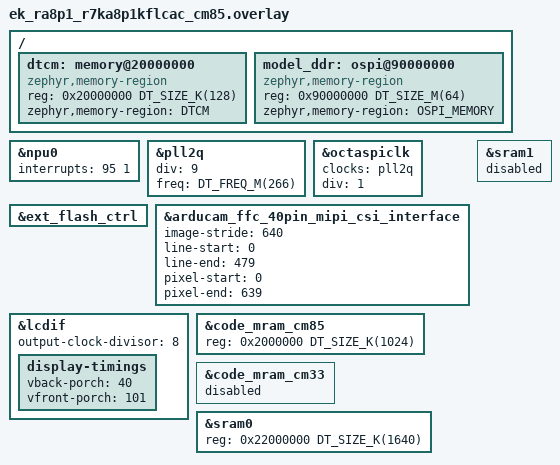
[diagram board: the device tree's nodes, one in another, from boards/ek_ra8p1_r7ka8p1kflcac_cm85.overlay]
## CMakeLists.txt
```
# Copyright 2026 Renesas Electronics Corporation
# SPDX-License-Identifier: Apache-2.0

cmake_minimum_required(VERSION 3.24)

set(CMAKE_SKIP_INSTALL_RULES
    ON
    CACHE BOOL "" FORCE
)

set(ET_PTE_FILE_PATH
    ""
    CACHE FILEPATH "Path to the ExecuTorch .pte (or .bpte) model to embed"
)
set(ET_PTE_SECTION
    "network_model_sec"
    CACHE STRING "Section attribute used for the generated model data"
)

if(NOT ET_PTE_FILE_PATH)
  message(
    FATAL_ERROR
      "ET_PTE_FILE_PATH must point to the ExecuTorch .pte (or .bpte) model to embed."
  )
endif()

if(NOT IS_ABSOLUTE "${ET_PTE_FILE_PATH}")
  get_filename_component(
    ET_PTE_FILE_PATH "${ET_PTE_FILE_PATH}" ABSOLUTE BASE_DIR
    "${CMAKE_CURRENT_SOURCE_DIR}"
  )
endif()

if(NOT EXISTS "${ET_PTE_FILE_PATH}")
  message(
    FATAL_ERROR
      "Could not find ExecuTorch model at ET_PTE_FILE_PATH: ${ET_PTE_FILE_PATH}"
  )
endif()

set(ET_PTE_FILE_PATH
    "${ET_PTE_FILE_PATH}"
    CACHE FILEPATH "Path to the ExecuTorch .pte (or .bpte) model to embed"
          FORCE
)

find_package(
  Python3
  COMPONENTS Interpreter
  REQUIRED
)

# Needed early (before project()) just for ZEPHYR_EXECUTORCH_MODULE_DIR, to
# locate gen_oplist.py without assuming this sample's own path nests inside
# the executorch checkout.
find_package(Zephyr REQUIRED HINTS $ENV{ZEPHYR_BASE})

execute_process(
  COMMAND
    ${Python3_EXECUTABLE}
    "${ZEPHYR_EXECUTORCH_MODULE_DIR}/codegen/tools/gen_oplist.py"
    --model_file_path=${ET_PTE_FILE_PATH}
    --output_path=${CMAKE_CURRENT_BINARY_DIR}/temp.yaml
  RESULT_VARIABLE GEN_OPLIST_RESULT
  OUTPUT_VARIABLE CMD_RESULT
  ERROR_VARIABLE GEN_OPLIST_ERROR
)

if(NOT GEN_OPLIST_RESULT EQUAL 0)
  message(
    FATAL_ERROR
      "gen_oplist.py failed with exit code ${GEN_OPLIST_RESULT}: ${GEN_OPLIST_ERROR}"
  )
endif()

if(CMD_RESULT MATCHES "aten::" OR CMD_RESULT MATCHES "dim_order_ops::")
  set(FOUND_OPS_IN_FILE "true")
else()
  set(FOUND_OPS_IN_FILE "false")
endif()

if(${FOUND_OPS_IN_FILE})
  set(EXECUTORCH_SELECT_OPS_LIST "")
  set(EXECUTORCH_SELECT_OPS_MODEL
      "${ET_PTE_FILE_PATH}"
      CACHE STRING "Select operators from this ExecuTorch model" FORCE
  )
  set(_EXECUTORCH_GEN_ZEPHYR_PORTABLE_OPS ON)
  message(
    "gen_oplist:  EXECUTORCH_SELECT_OPS_MODEL=${ET_PTE_FILE_PATH} is used to auto generate ops from"
  )
else()
  set(EXECUTORCH_SELECT_OPS_LIST "")
  set(EXECUTORCH_SELECT_OPS_MODEL "")
  set(_EXECUTORCH_GEN_ZEPHYR_PORTABLE_OPS OFF)
  message(
    "gen_oplist: No non-delegated ops were found in ${ET_PTE_FILE_PATH}; no ops added to build"
  )
endif()

dt_nodelabel(model_ddr_path NODELABEL "model_ddr")
if(model_ddr_path)
  configure_file(
    model_section.ld.in ${CMAKE_CURRENT_BINARY_DIR}/model_section.ld @ONLY
  )
  zephyr_linker_sources(SECTIONS ${CMAKE_CURRENT_BINARY_DIR}/model_section.ld)

  # EK-RA8P1's OSPI controller reads back bytes as b1-b0-b3-b2 when running
  # in octa mode, so the model PTE blob linked into model_ddr (ET_PTE_SECTION,
  # see model_section.ld.in) must be byte-swapped in the flashed hex image or
  # it reads back scrambled at runtime. Split the final image into an
  # internal-flash part (PTE section removed) and an OSPI-only part (PTE
  # section only), byte-swap the OSPI part, then remerge.
  find_program(SREC_CAT srec_cat REQUIRED)

  set(MERGED_HEX ${PROJECT_BINARY_DIR}/zephyr_merged.hex)

  add_custom_target(
    split_flash ALL
    DEPENDS zephyr_final
    # Main internal flash image, OSPI section removed
    COMMAND
      ${CMAKE_OBJCOPY} -R ${ET_PTE_SECTION} -O ihex
      $<TARGET_FILE:zephyr_final>
      ${PROJECT_BINARY_DIR}/zephyr_internal.hex
    # OSPI data only (intermediate)
    COMMAND
      ${CMAKE_OBJCOPY} -j ${ET_PTE_SECTION} -O ihex
      $<TARGET_FILE:zephyr_final>
      ${PROJECT_BINARY_DIR}/zephyr_ospi_raw.hex
    # Byte-swap the OSPI hex
    COMMAND
      ${SREC_CAT} ${PROJECT_BINARY_DIR}/zephyr_ospi_raw.hex -Intel
      -byte_swap 2 -o ${PROJECT_BINARY_DIR}/zephyr_ospi.hex -Intel
    COMMAND
      ${SREC_CAT} ${PROJECT_BINARY_DIR}/zephyr_internal.hex -Intel
      ${PROJECT_BINARY_DIR}/zephyr_ospi.hex -Intel -o ${MERGED_HEX}
      -Intel
    COMMENT "Splitting and byte-swapping OSPI (${ET_PTE_SECTION}) flash image for octa-mode read order"
  )
endif()

# Route the method/temp allocator pools to external SDRAM when the board
# provides one, since some boards' on-chip SRAM is too small to hold both
# pools for larger models (e.g. MobileNetV2 needs ~3 MiB combined).
dt_nodelabel(pool_sdram_path NODELABEL "sdram1")
if(pool_sdram_path)
  configure_file(
    pool_section.ld.in ${CMAKE_CURRENT_BINARY_DIR}/pool_section.ld @ONLY
  )
  zephyr_linker_sources(SECTIONS ${CMAKE_CURRENT_BINARY_DIR}/pool_section.ld)
endif()

project(executorch_mv2_ethosu_renesas)

set(CMAKE_CXX_FLAGS
    "${CMAKE_CXX_FLAGS} -Wall -Wno-switch -Wno-float-conversion -Wno-double-promotion -Wno-psabi -ffunction-sections -fdata-sections"
)

if(NOT DEFINED EXECUTORCH_DIR)
  message(
    STATUS
      "ZEPHYR_EXECUTORCH_MODULE_DIR set to : ${ZEPHYR_EXECUTORCH_MODULE_DIR}"
  )
  if(DEFINED ZEPHYR_EXECUTORCH_MODULE_DIR)
    set(EXECUTORCH_DIR ${ZEPHYR_EXECUTORCH_MODULE_DIR})
    message(
      STATUS "Using Zephyr module discovery: EXECUTORCH_DIR=${EXECUTORCH_DIR}"
    )
  else()
    message(
      FATAL_ERROR
        "ExecuTorch module not found. Ensure it's properly configured in your Zephyr workspace."
    )
  endif()
else()
  message(STATUS "Using predefined EXECUTORCH_DIR=${EXECUTORCH_DIR}")
endif()

set(EXECUTORCH_ROOT ${EXECUTORCH_DIR})
include(${EXECUTORCH_DIR}/tools/cmake/Utils.cmake)

if(NOT TARGET portable_kernels)
  set(EXECUTORCH_PORTABLE_BUILD_KERNELS_ONLY ON)
  add_subdirectory(
    ${EXECUTORCH_DIR}/kernels/portable
    ${CMAKE_CURRENT_BINARY_DIR}/executorch/kernels/portable
  )
  unset(EXECUTORCH_PORTABLE_BUILD_KERNELS_ONLY)
endif()
set(EXECUTORCH_OPS_LIB "")
if(_EXECUTORCH_GEN_ZEPHYR_PORTABLE_OPS)
  include(${EXECUTORCH_DIR}/tools/cmake/Codegen.cmake)
  if(NOT DEFINED EXECUTORCH_ENABLE_DTYPE_SELECTIVE_BUILD)
    set(EXECUTORCH_ENABLE_DTYPE_SELECTIVE_BUILD "")
  endif()
  gen_selected_ops(
    LIB_NAME
    "cpu_portable_ops_lib"
    OPS_SCHEMA_YAML
    ""
    ROOT_OPS
    "${EXECUTORCH_SELECT_OPS_LIST}"
    INCLUDE_ALL_OPS
    ""
    OPS_FROM_MODEL
    "${EXECUTORCH_SELECT_OPS_MODEL}"
    DTYPE_SELECTIVE_BUILD
    "${EXECUTORCH_ENABLE_DTYPE_SELECTIVE_BUILD}"
  )
  generate_bindings_for_kernels(
    LIB_NAME "cpu_portable_ops_lib" FUNCTIONS_YAML
    ${EXECUTORCH_DIR}/kernels/portable/functions.yaml DTYPE_SELECTIVE_BUILD
    "${EXECUTORCH_ENABLE_DTYPE_SELECTIVE_BUILD}"
  )
  gen_operators_lib(
    LIB_NAME
    "cpu_portable_ops_lib"
    KERNEL_LIBS
    portable_kernels
    DEPS
    executorch
    DTYPE_SELECTIVE_BUILD
    "${EXECUTORCH_ENABLE_DTYPE_SELECTIVE_BUILD}"
  )
  set(EXECUTORCH_OPS_LIB "cpu_portable_ops_lib")
endif()

set(_local_flatcc_root ${CMAKE_BINARY_DIR}/flatcc_src)
if(NOT EXISTS ${_local_flatcc_root}/CMakeLists.txt)
  file(MAKE_DIRECTORY ${_local_flatcc_root})
  execute_process(
    COMMAND ${CMAKE_COMMAND} -E copy_directory
            ${EXECUTORCH_DIR}/third-party/flatcc ${_local_flatcc_root}
  )
endif()
set(EXECUTORCH_FLATCC_SOURCE_ROOT
    ${_local_flatcc_root}
    CACHE PATH "" FORCE
)
set(EXECUTORCH_FLATCC_INSTALL_ROOT
    ${_local_flatcc_root}
    CACHE PATH "" FORCE
)

set(app_sources
    src/main.c
    src/camera.c
    src/display.c
    src/ai_processing.cpp
    ${EXECUTORCH_DIR}/examples/arm/executor_runner/arm_memory_allocator.cpp
)
target_sources(app PRIVATE ${app_sources})

set(_model_pte_header ${CMAKE_CURRENT_BINARY_DIR}/model_pte.h)
add_custom_command(
  OUTPUT ${_model_pte_header}
  COMMAND
    ${Python3_EXECUTABLE}
    ${EXECUTORCH_DIR}/examples/arm/executor_runner/pte_to_header.py --pte
    ${ET_PTE_FILE_PATH} --outdir ${CMAKE_CURRENT_BINARY_DIR} --section
    ${ET_PTE_SECTION}
  DEPENDS ${ET_PTE_FILE_PATH}
          ${EXECUTORCH_DIR}/examples/arm/executor_runner/pte_to_header.py
  COMMENT "Converting ${ET_PTE_FILE_PATH} to model_pte.h"
)
add_custom_target(gen_model_header DEPENDS ${_model_pte_header})
add_dependencies(app gen_model_header)

if(DEFINED CONFIG_EXECUTORCH_METHOD_ALLOCATOR_POOL_SIZE)
  target_compile_definitions(
    app
    PRIVATE
      ET_ARM_METHOD_ALLOCATOR_POOL_SIZE=${CONFIG_EXECUTORCH_METHOD_ALLOCATOR_POOL_SIZE}
  )
endif()
if(DEFINED CONFIG_EXECUTORCH_TEMP_ALLOCATOR_POOL_SIZE)
  target_compile_definitions(
    app
    PRIVATE
      ET_ARM_BAREMETAL_SCRATCH_TEMP_ALLOCATOR_POOL_SIZE=${CONFIG_EXECUTORCH_TEMP_ALLOCATOR_POOL_SIZE}
  )
endif()
if(CONFIG_ET_ARM_MODEL_PTE_DMA_ACCESSIBLE)
  target_compile_definitions(app PRIVATE ET_ARM_MODEL_PTE_DMA_ACCESSIBLE)
endif()

target_link_libraries(app PRIVATE libexecutorch)
target_compile_options(libexecutorch PRIVATE -w)
if(EXECUTORCH_OPS_LIB)
  target_link_libraries(app PRIVATE ${EXECUTORCH_OPS_LIB})
  target_compile_options(${EXECUTORCH_OPS_LIB} PRIVATE -w)
endif()
if(CONFIG_CPU_CORTEX_M)
  if(TARGET cortex_m_ops_lib)
    target_link_libraries(app PRIVATE cortex_m_ops_lib)
    target_compile_options(cortex_m_ops_lib PRIVATE -w)
  endif()
  if(TARGET cortex_m_kernels)
    executorch_target_link_options_shared_lib(cortex_m_kernels)
    target_link_libraries(app PRIVATE cortex_m_kernels)
    target_compile_options(cortex_m_kernels PRIVATE -w)
  endif()
endif()
if(TARGET quantized_kernels)
  executorch_target_link_options_shared_lib(quantized_kernels)
  target_link_libraries(app PRIVATE quantized_kernels)
  target_compile_options(quantized_kernels PRIVATE -w)
endif()
if(TARGET portable_kernels)
  executorch_target_link_options_shared_lib(portable_kernels)
  target_link_libraries(app PRIVATE portable_kernels)
  target_compile_options(portable_kernels PRIVATE -w)
endif()
if(TARGET executorch_delegate_ethos_u)
  executorch_target_link_options_shared_lib(executorch_delegate_ethos_u)
  target_link_libraries(app PRIVATE executorch_delegate_ethos_u)
  target_compile_options(executorch_delegate_ethos_u PRIVATE -w)
endif()
if(TARGET ethosu_core_driver)
  target_link_libraries(app PRIVATE ethosu_core_driver)
  target_compile_options(ethosu_core_driver PRIVATE -w)
endif()

target_include_directories(app PRIVATE src ${CMAKE_CURRENT_BINARY_DIR})
get_target_property(OUT app LINK_LIBRARIES)
message(STATUS ${OUT})
```

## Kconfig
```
# Copyright 2026 Renesas Electronics Corporation
# SPDX-License-Identifier: Apache-2.0

mainmenu "ExecuTorch MobileNetV2 live camera classification (Renesas EK-RA8P1)"

menu "Video capture configuration"

config VIDEO_WIDTH
	int "Define the width of the video"
	default 640

config VIDEO_HEIGHT
	int "Define the height of the video"
	default 480

endmenu

config OSPI_OPTIMINE_DUMMY_CYCLES
	bool "Optimize OSPI dummy cycles for speed"
	default y
	help
	  When enabled, the OSPI driver will attempt to optimize dummy cycles
	  for faster read/write operations. This may improve performance on
	  supported hardware.

menu "Screen Configuration"

config SCREEN_ORIENTATION
	int "Screen orientation"
	default 90
	help
	  Orientation of the screen in degrees (0, 90, 180, 270).

config SCREEN_WIDTH
	int "Screen width"
	default 1024
	help
	  Width of the screen in pixels. Matches the native 1024x600
	  resolution of the rtklcdpar1s00001be shield's panel on the EK-RA8P1.
	  VIDEO_WIDTH/HEIGHT does not have to match this
	  exactly - display.c puts the video in a 640x480 LVGL canvas at
	  (0,0) against the panel's def-back-color background (see the board
	  overlay's &lcdif), letterboxing whatever doesn't fit.

config SCREEN_HEIGHT
	int "Screen height"
	default 600
	help
	  Height of the screen in pixels.
endmenu

menu "AI Configuration"

config AI_INPUT_WIDTH
	int "AI input image width"
	default 224
	help
	  Width of the input image for the MobileNetV2 model.

config AI_INPUT_HEIGHT
	int "AI input image height"
	default 224
	help
	  Height of the input image for the MobileNetV2 model.

config ET_ARM_MODEL_PTE_DMA_ACCESSIBLE
	bool "Model PTE is in DMA-accessible memory"
	default y
	help
	  Skip copying the model PTE blob to a separate SRAM buffer at
	  runtime. Enable this when the embedded model blob already resides
	  in memory the Ethos-U NPU can DMA from (e.g. DDR on Corstone FVP,
	  MRAM on Alif). This is independent of where the linker places the
	  model section; DDR placement is controlled by the model_ddr DTS
	  node in the board overlay.

config EXECUTORCH_METHOD_ALLOCATOR_POOL_SIZE
	int "Method allocator pool size in bytes"
	default 1572864
	depends on EXECUTORCH
	help
	  Size of the method allocator pool in bytes. MobileNetV2 requires
	  more memory than simple models. Default is 1.5MB which is sufficient
	  for a fully NPU-delegated INT8 MobileNetV2 model.

config EXECUTORCH_TEMP_ALLOCATOR_POOL_SIZE
	int "Temporary allocator pool size in bytes"
	default 1572864
	depends on EXECUTORCH
	help
	  Size of the temporary allocator pool in bytes. Default is 1.5MB
	  which provides sufficient scratch space for MobileNetV2 inference
	  on Ethos-U NPU.

config AI_INPUT_QUANT_SCALE
	string "Input tensor quantization scale"
	default "0.0078"
	help
	  Input tensor's quantization scale, as printed by
	  export_quantized_io.py's "Quantized input 0 ..." line for the
	  exported .pte. Must match the .pte exactly - the runtime has no
	  way to read this back from the tensor itself. Update this
	  whenever the .pte is re-exported; input scale has reproduced
	  identically across export runs so far (unlike output, see
	  AI_OUTPUT_QUANT_SCALE), but verify against the .pte you're
	  actually flashing rather than assuming.

config AI_INPUT_QUANT_ZERO_POINT
	int "Input tensor quantization zero point"
	default 0
	help
	  Input tensor's quantization zero point, as printed by
	  export_quantized_io.py's "Quantized input 0 ..." line for the
	  exported .pte. Must match the .pte exactly.

config AI_OUTPUT_QUANT_SCALE
	string "Output tensor quantization scale"
	default "0.1004"
	help
	  Output tensor's quantization scale, as printed by
	  export_quantized_io.py's "Quantized output 0 ..." line for the
	  exported .pte. Must match the .pte exactly - the runtime has no
	  way to read this back from the tensor itself. Unlike input, this
	  has NOT reproduced identically across export runs (calibration-
	  order sensitivity in the AoT HistogramObserver) - re-check and
	  update whenever the .pte is re-exported, against the .pte you're
	  actually flashing.

config AI_OUTPUT_QUANT_ZERO_POINT
	int "Output tensor quantization zero point"
	default 127
	help
	  Output tensor's quantization zero point, as printed by
	  export_quantized_io.py's "Quantized output 0 ..." line for the
	  exported .pte. Same calibration-order sensitivity caveat as
	  AI_OUTPUT_QUANT_SCALE.

config AI_OUTPUT_SCORE_AS_PERCENT
	bool "Log classification score as softmax percent instead of raw logit"
	default y
	help
	  When enabled, get_top_k() logs each top-K class's score as a
	  softmax-normalized percentage (0-100%) over all classes. When
	  disabled, the raw logit value from the output tensor is logged
	  as-is.

config APP_RUNTIME_LOG
	bool "Print per-frame runtime console output"
	default n
	help
	  Print the top-K results and inference time to the console for every
	  frame. Each line is a synchronous console write, so keep this off
	  when measuring latency or running the demo. Init logs and the
	  on-screen result panel are not affected.

config APP_PROFILING
	bool "Measure and log per-stage pipeline latency"
	default n
	help
	  Log average/max latency per pipeline stage (preprocess, inference,
	  postprocess, end-to-end, video) every APP_PROFILING_PERIOD results.
	  Time starts when camera_task dequeues the frame, so sensor exposure
	  is not included. Keep APP_RUNTIME_LOG off: its console writes would
	  count as postprocess time.

config APP_SERIALIZE_FRAMES
	bool "Process one AI frame at a time, from capture to flush finished"
	default n
	help
	  Hand a camera frame to the AI pipeline only after the result of the
	  previous AI frame has been flushed to the display. Frames in between
	  are shown as video only. This removes queueing and CPU contention
	  between frames so the latencies are those of a single frame, at the
	  cost of AI throughput.

config APP_PROFILING_PERIOD
	int "Results per profiling report"
	default 30
	range 1 1000
	depends on APP_PROFILING
	help
	  Number of inference results averaged into each report.

endmenu

menu "Thread Stack Sizes"

config AI_THREAD_STACK_SIZE
	int "AI task stack size"
	default 16384
	help
	  Stack size for the AI (ExecuTorch inference) processing task.

config CAMERA_THREAD_STACK_SIZE
	int "Camera task stack size"
	default 4096
	help
	  Stack size for the camera capture task.

config DISPLAY_THREAD_STACK_SIZE
	int "Display task stack size"
	default 4096
	help
	  Stack size for the display task.

config AI_PREPROCESS_THREAD_STACK_SIZE
	int "AI preprocess task stack size"
	default 2048
	help
	  Stack size for the RGB565->planar-RGB888 AI input conversion task.
	  No ExecuTorch method/temp allocator pools involved here (that's
	  AI_THREAD_STACK_SIZE), just the conversion loop's local state.

endmenu

source "Kconfig.zephyr"
```

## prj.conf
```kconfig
# Copyright 2026 Renesas Electronics Corporation
# SPDX-License-Identifier: Apache-2.0

# Enable ExecuTorch
CONFIG_EXECUTORCH=y

# C++
CONFIG_CPP=y
CONFIG_STD_CPP17=y

# Config - sized for MobileNetV2 + camera + display running together
CONFIG_MAIN_STACK_SIZE=16384
CONFIG_HEAP_MEM_POOL_SIZE=65536

# Logging
CONFIG_LOG=y
CONFIG_REQUIRES_FLOAT_PRINTF=y

# Configuration for selective operator builds
CONFIG_EXECUTORCH_BUILD_PORTABLE_OPS=n

# Enable Helium (MVE) builds of CMSIS-NN by selecting the FPU and hard-float ABI.
CONFIG_FPU=y
CONFIG_FP_HARDABI=y

# Camera capture (OV5640 via the Zephyr video API)
CONFIG_VIDEO=y

CONFIG_DISPLAY=y
CONFIG_DISPLAY_LOG_LEVEL_ERR=y

CONFIG_LVGL=y
CONFIG_LV_CONF_MINIMAL=y
CONFIG_LV_USE_IMAGE=y
CONFIG_LV_USE_LABEL=y
CONFIG_LV_USE_CANVAS=y
CONFIG_LV_COLOR_DEPTH_16=y
CONFIG_LV_Z_MEM_POOL_SIZE=58368
CONFIG_LV_Z_VDB_SIZE=100
CONFIG_LV_Z_DOUBLE_VDB=y
CONFIG_LV_FONT_MONTSERRAT_24=y
CONFIG_LV_USE_SYSMON=y
CONFIG_LV_USE_PERF_MONITOR=y

CONFIG_CPU_LOAD=y
```

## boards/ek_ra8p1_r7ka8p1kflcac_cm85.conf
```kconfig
# Copyright 2026 Renesas Electronics Corporation
# SPDX-License-Identifier: Apache-2.0

CONFIG_FLASH=y
CONFIG_MEMC=y

# USER NEED UPDATE AFTER EACH TIME EXPORT MODEL
CONFIG_AI_INPUT_QUANT_SCALE="0.007808685302734375"
CONFIG_AI_INPUT_QUANT_ZERO_POINT=0
CONFIG_AI_OUTPUT_QUANT_SCALE="0.10048583149909973"
CONFIG_AI_OUTPUT_QUANT_ZERO_POINT=127

# cortex-m85 specific configurations
# CONFIG_EXECUTORCH_TEMP_ALLOCATOR_POOL_SIZE=0
# CONFIG_EXECUTORCH_METHOD_ALLOCATOR_POOL_SIZE=900000

# ETHOS-U specific configurations
CONFIG_ETHOS_U=y
CONFIG_EXECUTORCH_TEMP_ALLOCATOR_POOL_SIZE=804928
CONFIG_EXECUTORCH_METHOD_ALLOCATOR_POOL_SIZE=452880

CONFIG_VIDEO_BUFFER_POOL_HEAP_SIZE=5200282
CONFIG_VIDEO_BUFFER_POOL_NUM_MAX=8
CONFIG_VIDEO_BUFFER_POOL_ZEPHYR_REGION=y
CONFIG_VIDEO_BUFFER_POOL_ZEPHYR_REGION_NAME="SDRAM"

CONFIG_LV_USE_DRAW_DAVE2D=y
CONFIG_RENESAS_DAVE2D_RUNTIME_HEAP_SIZE=49752

# VDB routed to SDRAM (overrides prj.conf's default region for this board).
CONFIG_LV_Z_VDB_ZEPHYR_REGION=y
CONFIG_LV_Z_VDB_ZEPHYR_REGION_NAME="SDRAM"

CONFIG_LV_Z_USE_OSAL=y
CONFIG_LV_DRAW_THREAD_PRIO=-2

CONFIG_DYNAMIC_THREAD=y
CONFIG_DYNAMIC_THREAD_ALLOC=y

CONFIG_DCACHE=y
CONFIG_CACHE_MANAGEMENT=y
```

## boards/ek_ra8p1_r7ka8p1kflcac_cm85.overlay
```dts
/*
 * Copyright (c) 2026 Renesas Electronics Corporation
 * SPDX-License-Identifier: Apache-2.0
 */

&npu0 {
	interrupts = <95 1>;
	interrupt-names = "npu-irq";
	status = "okay";
};

&pll2q {
	div = <9>;
	freq = <DT_FREQ_M(266)>;
};

&octaspiclk {
	clocks = <&pll2q>;
	div = <1>;
};

&ext_flash_ctrl {
	status = "okay";
};

&arducam_ffc_40pin_mipi_csi_interface {
	image-stride = <640>;
	line-start = <0>;
	line-end = <479>;
	pixel-start = <0>;
	pixel-end = <639>;
};

&lcdif {
	output-clock-divisor = <8>;

	display-timings {
		vback-porch = <40>;
		vfront-porch = <101>;
	};
};

/ {
	dtcm: memory@20000000 {
		compatible = "zephyr,memory-region", "arm,dtcm";
		reg = <0x20000000 DT_SIZE_K(128)>;
		zephyr,memory-region = "DTCM";
	};

	model_ddr: ospi@90000000 {
		compatible = "zephyr,memory-region";
		reg = <0x90000000 DT_SIZE_M(64)>;
		zephyr,memory-region = "OSPI_MEMORY";
	};
};

&code_mram_cm85 {
	reg = <0x2000000 DT_SIZE_K(1024)>;
};

&code_mram_cm33 {
	status = "disabled";
};

&sram0 {
	reg = <0x22000000 DT_SIZE_K(1640)>;
};

&sram1 {
	status = "disabled";
};
```

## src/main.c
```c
/*
 * Copyright (c) 2026 Renesas Electronics Corporation
 *
 * SPDX-License-Identifier: Apache-2.0
 */

#include <zephyr/logging/log.h>

#include "ai_processing.h"
#include "camera.h"
#include "display.h"
#include "common_util.h"

#ifdef CONFIG_SOC_SERIES_RA8P1
#include <soc.h>

static void ra8p1_bus_arbitration_round_robin(void)
{
	R_BUS->BUSMABT_b.ARBS = 1;
	R_BUS->BUSSABT0.MRE0BI_b.ARBS = 1;
}
#endif /* CONFIG_SOC_SERIES_RA8P1 */

K_THREAD_STACK_DEFINE(camera_stack_area, CONFIG_CAMERA_THREAD_STACK_SIZE);
K_THREAD_STACK_DEFINE(display_stack_area, CONFIG_DISPLAY_THREAD_STACK_SIZE);
K_THREAD_STACK_DEFINE(ai_preprocess_stack_area, CONFIG_AI_PREPROCESS_THREAD_STACK_SIZE);
K_THREAD_STACK_DEFINE(ai_stack_area, CONFIG_AI_THREAD_STACK_SIZE);

LOG_MODULE_REGISTER(main, CONFIG_LOG_DEFAULT_LEVEL);

static struct k_thread camera_thread;
static struct k_thread display_thread;
static struct k_thread ai_preprocess_thread;
static struct k_thread ai_thread;

K_MSGQ_DEFINE(display_frame_msgq, sizeof(camera_frame_msg_t), DISPLAY_QUEUE_DEPTH, 4);
K_MSGQ_DEFINE(ai_raw_frame_msgq, sizeof(camera_frame_msg_t), AI_RAW_FRAME_QUEUE_DEPTH, 4);
K_MSGQ_DEFINE(ai_input_msgq, sizeof(ai_input_msg_t), AI_INPUT_QUEUE_DEPTH, 4);
K_MSGQ_DEFINE(ai_result_msgq, sizeof(ai_result_msg_t), AI_RESULT_QUEUE_DEPTH, 4);

int main(void)
{
	LOG_INF("ExecuTorch MobileNetV2 live camera classification (mv2-ethosu-renesas)");

	int ret;

#ifdef CONFIG_SOC_SERIES_RA8P1
	ra8p1_bus_arbitration_round_robin();
#endif
	ret = camera_init();
	if (ret != 0) {
		LOG_ERR("Camera initialization failed");
		return 0;
	}

	ret = display_init();
	if (ret != 0) {
		LOG_ERR("Display initialization failed");
		return 0;
	}

	ret = ai_init();
	if (ret != 0) {
		LOG_ERR("AI (ExecuTorch) initialization failed");
		return 0;
	}

	k_thread_create(&camera_thread, camera_stack_area, K_THREAD_STACK_SIZEOF(camera_stack_area),
			camera_task, &display_frame_msgq, &ai_raw_frame_msgq, NULL,
			CAMERA_THREAD_PRIORITY, 0, K_NO_WAIT);

	k_thread_create(&ai_preprocess_thread, ai_preprocess_stack_area,
			K_THREAD_STACK_SIZEOF(ai_preprocess_stack_area), camera_ai_preprocess_task,
			&ai_raw_frame_msgq, &ai_input_msgq, NULL, AI_PREPROCESS_THREAD_PRIORITY, 0,
			K_NO_WAIT);

	k_thread_create(&ai_thread, ai_stack_area, K_THREAD_STACK_SIZEOF(ai_stack_area), ai_task,
			&ai_input_msgq, &ai_result_msgq, NULL, AI_THREAD_PRIORITY, 0, K_NO_WAIT);

	k_thread_create(&display_thread, display_stack_area,
			K_THREAD_STACK_SIZEOF(display_stack_area), display_task,
			&display_frame_msgq, &ai_result_msgq, NULL, DISPLAY_THREAD_PRIORITY, 0,
			K_NO_WAIT);

	k_sleep(K_FOREVER);

	return 0;
}
```

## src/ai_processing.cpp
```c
/*
 * Copyright 2026 Renesas Electronics Corporation
 *
 * SPDX-License-Identifier: Apache-2.0
 */
#include <zephyr/kernel.h>
#include <zephyr/logging/log.h>

#include <executorch/examples/arm/executor_runner/arm_memory_allocator.h>
#include <executorch/extension/data_loader/buffer_data_loader.h>
#include <executorch/runtime/executor/program.h>
#include <executorch/runtime/platform/log.h>
#include <executorch/runtime/platform/platform.h>
#include <executorch/runtime/platform/runtime.h>
#include <algorithm>
#include <cmath>
#include <cstdlib>
#include <cstring>
#include <vector>

#include "ai_processing.h"
#include "common_util.h"
#include "imagenet_labels.h"
#include "model_pte.h"

LOG_MODULE_REGISTER(ai_processing, CONFIG_LOG_DEFAULT_LEVEL);

#if defined(ET_ARM_MODEL_PTE_DMA_ACCESSIBLE)
static const unsigned char *model_pte_ptr = model_pte;
#else
alignas(16) static unsigned char model_pte_runtime[sizeof(model_pte)];
static bool model_pte_runtime_initialized = false;
#endif

using executorch::aten::ScalarType;
using executorch::aten::Tensor;
using executorch::extension::BufferDataLoader;
using executorch::runtime::Error;
using executorch::runtime::EValue;
using executorch::runtime::HierarchicalAllocator;
using executorch::runtime::MemoryManager;
using executorch::runtime::Method;
using executorch::runtime::MethodMeta;
using executorch::runtime::Program;
using executorch::runtime::Result;
using executorch::runtime::Span;
using executorch::runtime::Tag;
using executorch::runtime::TensorInfo;

namespace
{

#if !defined(ET_ARM_METHOD_ALLOCATOR_POOL_SIZE)
#define ET_ARM_METHOD_ALLOCATOR_POOL_SIZE (1572864)
#endif
const size_t method_allocation_pool_size = ET_ARM_METHOD_ALLOCATOR_POOL_SIZE;
unsigned char __attribute__((section(".bss.method_pool"),
			     aligned(16))) method_allocation_pool[method_allocation_pool_size];

#if !defined(ET_ARM_BAREMETAL_SCRATCH_TEMP_ALLOCATOR_POOL_SIZE)
#define ET_ARM_BAREMETAL_SCRATCH_TEMP_ALLOCATOR_POOL_SIZE (1572864)
#endif
const size_t temp_allocation_pool_size = ET_ARM_BAREMETAL_SCRATCH_TEMP_ALLOCATOR_POOL_SIZE;
unsigned char __attribute__((section(".bss.tensor_arena"),
			     aligned(16))) temp_allocation_pool[temp_allocation_pool_size];

#if !defined(ET_ARM_BAREMETAL_FAST_SCRATCH_TEMP_ALLOCATOR_POOL_SIZE)
#define ET_ARM_BAREMETAL_FAST_SCRATCH_TEMP_ALLOCATOR_POOL_SIZE 0x600
#endif
extern "C" {
size_t ethosu_fast_scratch_size = ET_ARM_BAREMETAL_FAST_SCRATCH_TEMP_ALLOCATOR_POOL_SIZE;
unsigned char __attribute__((
	section(".bss.ethosu_scratch"),
	aligned(16))) dedicated_sram[ET_ARM_BAREMETAL_FAST_SCRATCH_TEMP_ALLOCATOR_POOL_SIZE];
unsigned char *ethosu_fast_scratch = dedicated_sram;
}

ArmMemoryAllocator method_allocator(method_allocation_pool_size, method_allocation_pool);
ArmMemoryAllocator temp_allocator(temp_allocation_pool_size, temp_allocation_pool);

BufferDataLoader *g_loader = nullptr;
Result<Program> *g_program = nullptr;
Result<Method> *g_method = nullptr;
HierarchicalAllocator *g_planned_memory = nullptr;
MemoryManager *g_memory_manager = nullptr;

std::vector<uint8_t *> g_planned_buffers;
std::vector<Span<uint8_t>> g_planned_spans;
std::vector<EValue> g_outputs;

void *g_input_data_ptr = nullptr;
size_t g_input_num_elements = 0;

const float OUTPUT_QUANT_SCALE = strtof(CONFIG_AI_OUTPUT_QUANT_SCALE, nullptr);
constexpr int32_t OUTPUT_QUANT_ZERO_POINT = CONFIG_AI_OUTPUT_QUANT_ZERO_POINT;

/* uint8 camera byte -> int8 model input, normalized as (v - 128) / 128 */
#define INPUT_QUANT_MIN (-128)
#define INPUT_QUANT_MAX (127)

const float INPUT_QUANT_SCALE = strtof(CONFIG_AI_INPUT_QUANT_SCALE, nullptr);
constexpr int32_t INPUT_QUANT_ZERO_POINT = CONFIG_AI_INPUT_QUANT_ZERO_POINT;

int8_t g_input_lut[256];

void init_input_lut()
{
	for (int v = 0; v < 256; v++) {
		float x = (static_cast<float>(v) - 128.0f) / 128.0f;
		float q = std::round(x / INPUT_QUANT_SCALE) + INPUT_QUANT_ZERO_POINT;
		q = std::max(static_cast<float>(INPUT_QUANT_MIN),
			     std::min(static_cast<float>(INPUT_QUANT_MAX), q));
		g_input_lut[v] = static_cast<int8_t>(q);
	}
}

#define AI_TOP_K 5

st_ai_classification_point_t g_top_k_results[AI_TOP_K];

/* The model input is memory-planned, so Method::set_input() would only memcpy
 * a separate buffer into it every frame. Write straight into the planned
 * tensor instead. get_input() is deprecated upstream but is the only way to
 * reach it.
 */
Error get_input_buffer(Method &method, void **out_data_ptr, size_t *out_numel)
{
	MethodMeta method_meta = method.method_meta();

	if (method_meta.num_inputs() != 1) {
		ET_LOG(Error, "Model has %zu inputs; this sample supports exactly one",
		       method_meta.num_inputs());
		return Error::InvalidArgument;
	}

	auto tag = method_meta.input_tag(0);
	if (!tag.ok()) {
		return tag.error();
	}
	if (tag.get() != Tag::Tensor) {
		ET_LOG(Error, "Model input 0 is not a tensor");
		return Error::InvalidArgument;
	}

	Result<TensorInfo> tensor_meta = method_meta.input_tensor_meta(0);
	if (!tensor_meta.ok()) {
		return tensor_meta.error();
	}

	if (tensor_meta->scalar_type() != ScalarType::Char) {
		ET_LOG(Error,
		       "Model input is %s, expected int8 - export with export_quantized_io.py",
		       executorch::runtime::toString(tensor_meta->scalar_type()));
		return Error::InvalidArgument;
	}

	if (!tensor_meta->is_memory_planned()) {
		ET_LOG(Error, "Model input is not memory-planned, so it has no buffer to write to");
		return Error::InvalidArgument;
	}

#pragma GCC diagnostic push
#pragma GCC diagnostic ignored "-Wdeprecated-declarations"
	const Tensor input = method.get_input(0).toTensor();
#pragma GCC diagnostic pop

	if (input.mutable_data_ptr() == nullptr) {
		ET_LOG(Error, "Model input has no backing memory");
		return Error::InvalidState;
	}

	ET_LOG(Info, "Input tensor: scalar_type=%s, numel=%lu, nbytes=%lu",
	       executorch::runtime::toString(tensor_meta->scalar_type()),
	       static_cast<unsigned long>(input.numel()),
	       static_cast<unsigned long>(tensor_meta->nbytes()));

	*out_data_ptr = input.mutable_data_ptr();
	*out_numel = static_cast<size_t>(input.numel());
	return Error::Ok;
}

void get_top_k(const std::vector<EValue> &outputs)
{
	if (outputs.empty() || !outputs[0].isTensor()) {
		ET_LOG(Error, "Output is not a tensor");
		return;
	}

	Tensor output_tensor = outputs[0].toTensor();
	ScalarType scalar_type = output_tensor.scalar_type();
	size_t num_classes = output_tensor.numel();

	int top_indices[AI_TOP_K] = {0};
	float top_values[AI_TOP_K];

	for (int j = 0; j < AI_TOP_K; j++) {
		top_values[j] = -1e9f;
	}

	float max_val = 0.0f;

	for (size_t i = 0; i < num_classes; i++) {
		float val;
		switch (scalar_type) {
		case ScalarType::Float:
			val = output_tensor.const_data_ptr<float>()[i];
			break;
		case ScalarType::Int:
			val = static_cast<float>(output_tensor.const_data_ptr<int>()[i]);
			break;
		case ScalarType::Char:
			val = (static_cast<float>(output_tensor.const_data_ptr<int8_t>()[i]) -
			       OUTPUT_QUANT_ZERO_POINT) *
			      OUTPUT_QUANT_SCALE;
			break;
		case ScalarType::Byte:
			val = (static_cast<float>(output_tensor.const_data_ptr<uint8_t>()[i]) -
			       OUTPUT_QUANT_ZERO_POINT) *
			      OUTPUT_QUANT_SCALE;
			break;
		default:
			ET_LOG(Error, "Unsupported output scalar type: %s",
			       executorch::runtime::toString(scalar_type));
			return;
		}

		if (i == 0 || val > max_val) {
			max_val = val;
		}

		for (int j = 0; j < AI_TOP_K; j++) {
			if (val > top_values[j]) {
				for (int m = AI_TOP_K - 1; m > j; m--) {
					top_values[m] = top_values[m - 1];
					top_indices[m] = top_indices[m - 1];
				}
				top_values[j] = val;
				top_indices[j] = static_cast<int>(i);
				break;
			}
		}
	}

	double sum_exp = 0.0;
	for (size_t i = 0; i < num_classes; i++) {
		float val;
		switch (scalar_type) {
		case ScalarType::Float:
			val = output_tensor.const_data_ptr<float>()[i];
			break;
		case ScalarType::Int:
			val = static_cast<float>(output_tensor.const_data_ptr<int>()[i]);
			break;
		case ScalarType::Char:
			val = (static_cast<float>(output_tensor.const_data_ptr<int8_t>()[i]) -
			       OUTPUT_QUANT_ZERO_POINT) *
			      OUTPUT_QUANT_SCALE;
			break;
		case ScalarType::Byte:
			val = (static_cast<float>(output_tensor.const_data_ptr<uint8_t>()[i]) -
			       OUTPUT_QUANT_ZERO_POINT) *
			      OUTPUT_QUANT_SCALE;
			break;
		default:
			val = 0.0f;
			break;
		}
		sum_exp += std::exp(static_cast<double>(val - max_val));
	}

	double top_prob[AI_TOP_K];
	double top_prob_sum = 1e-6;
	for (int j = 0; j < AI_TOP_K; j++) {
		top_prob[j] = std::exp(static_cast<double>(top_values[j] - max_val)) / sum_exp;
		top_prob_sum += top_prob[j];
	}

	if (IS_ENABLED(CONFIG_APP_RUNTIME_LOG)) {
		ET_LOG(Info, "\nTop-%d predictions:", AI_TOP_K);
	}
	for (int j = 0; j < AI_TOP_K; j++) {
		int idx = top_indices[j];
		const char *label =
			(idx >= 0 && idx < IMAGENET_NUM_CLASSES) ? imagenet_labels[idx] : "?";
		double probability = top_prob[j] / top_prob_sum;

		g_top_k_results[j].label_idx = static_cast<uint32_t>(idx);
		g_top_k_results[j].label = label;
		g_top_k_results[j].probability = static_cast<float>(probability);

		if (!IS_ENABLED(CONFIG_APP_RUNTIME_LOG)) {
			continue;
		}
#if defined(CONFIG_AI_OUTPUT_SCORE_AS_PERCENT)
		ET_LOG(Info, "  [%d] class %d (%s): %.2f%%", j + 1, idx, label,
		       probability * 100.0);
#else
		ET_LOG(Info, "  [%d] class %d (%s): %.4f", j + 1, idx, label,
		       static_cast<double>(top_values[j]));
#endif
	}
}

} // namespace

extern "C" int ai_init(void)
{
	executorch::runtime::runtime_init();
	init_input_lut();

	size_t pte_size = sizeof(model_pte);
	ET_LOG(Info, "Model PTE at %p, Size: %lu bytes", model_pte,
	       static_cast<unsigned long>(pte_size));

#if defined(ET_ARM_MODEL_PTE_DMA_ACCESSIBLE)
	const void *program_data = model_pte_ptr;
#else
	if (!model_pte_runtime_initialized) {
		std::memcpy(model_pte_runtime, model_pte, sizeof(model_pte));
		model_pte_runtime_initialized = true;
	}
	const void *program_data = model_pte_runtime;
#endif
	size_t program_data_len = pte_size;
	g_loader = new BufferDataLoader(program_data, program_data_len);

	ET_LOG(Info, "Model data loaded. Size: %lu bytes.",
	       static_cast<unsigned long>(program_data_len));

	g_program = new Result<Program>(Program::load(g_loader));

	if (!(*g_program).ok()) {
		ET_LOG(Error, "Program loading failed @ 0x%p: 0x%" PRIx32, program_data,
		       static_cast<uint32_t>((*g_program).error()));
		return 1;
	}

	ET_LOG(Info, "Model loaded, has %lu methods",
	       static_cast<unsigned long>((*g_program)->num_methods()));

	const char *method_name = nullptr;
	{
		const auto method_name_result = (*g_program)->get_method_name(0);
		ET_CHECK_MSG(method_name_result.ok(), "Program has no methods");
		method_name = *method_name_result;
	}
	ET_LOG(Info, "Running method: %s", method_name);

	Result<MethodMeta> method_meta = (*g_program)->method_meta(method_name);
	if (!method_meta.ok()) {
		ET_LOG(Error, "Failed to get method_meta for %s: 0x%x", method_name,
		       (unsigned int)method_meta.error());
		return 1;
	}

	ET_LOG(Info, "Method allocator pool size: %lu bytes.",
	       static_cast<unsigned long>(method_allocation_pool_size));

	size_t num_memory_planned_buffers = method_meta->num_memory_planned_buffers();

	for (size_t id = 0; id < num_memory_planned_buffers; ++id) {
		Result<int64_t> buffer_size_result = method_meta->memory_planned_buffer_size(id);
		if (!buffer_size_result.ok()) {
			ET_LOG(Error, "Failed to get planned buffer size for buffer %lu: 0x%x",
			       static_cast<unsigned long>(id),
			       (unsigned int)buffer_size_result.error());
			return 1;
		}
		size_t buffer_size = static_cast<size_t>(buffer_size_result.get());
		ET_LOG(Info, "Setting up planned buffer %lu, size %lu.",
		       static_cast<unsigned long>(id), static_cast<unsigned long>(buffer_size));

		uint8_t *buffer =
			reinterpret_cast<uint8_t *>(method_allocator.allocate(buffer_size));
		ET_CHECK_MSG(buffer != nullptr, "Could not allocate planned buffer size %lu",
			     static_cast<unsigned long>(buffer_size));
		g_planned_buffers.push_back(buffer);
		g_planned_spans.push_back({g_planned_buffers.back(), buffer_size});
	}

	g_planned_memory =
		new HierarchicalAllocator({g_planned_spans.data(), g_planned_spans.size()});

	g_memory_manager = new MemoryManager(&method_allocator, g_planned_memory, &temp_allocator);

	ET_LOG(Info, "Loading method...");
	executorch::runtime::EventTracer *event_tracer_ptr = nullptr;

	g_method = new Result<Method>(
		(*g_program)->load_method(method_name, g_memory_manager, event_tracer_ptr));

	if (!(*g_method).ok()) {
		ET_LOG(Error, "Loading of method %s failed with status 0x%" PRIx32, method_name,
		       static_cast<uint32_t>((*g_method).error()));
		return 1;
	}
	ET_LOG(Info, "Method '%s' loaded successfully", method_name);

	Error input_err = ::get_input_buffer(**g_method, &g_input_data_ptr, &g_input_num_elements);

	if (input_err != Error::Ok) {
		ET_LOG(Error, "Getting input buffer failed: 0x%" PRIx32,
		       static_cast<uint32_t>(input_err));
		return 1;
	}

	g_outputs.resize((*g_method)->outputs_size());

	ET_LOG(Info, "Method allocator: used %lu of %lu bytes",
	       static_cast<unsigned long>(method_allocator.used_size()),
	       static_cast<unsigned long>(method_allocation_pool_size));

	ET_LOG(Info, "Model size: %lu bytes", static_cast<unsigned long>(pte_size));
	ET_LOG(Info, "Input tensor: %lu bytes", static_cast<unsigned long>(g_input_num_elements));
	return 0;
}

void ai_task(void *arg1, void *arg2, void *arg3)
{
	ARG_UNUSED(arg3);

	struct k_msgq *ai_input_msgq = (struct k_msgq *)arg1;
	struct k_msgq *ai_result_msgq = (struct k_msgq *)arg2;
	ai_input_msg_t ai_input_msg;

	for (;;) {
		if (k_msgq_get(ai_input_msgq, &ai_input_msg, K_FOREVER) != 0) {
			continue;
		}

		if (ai_input_msg.size != g_input_num_elements) {
			ET_LOG(Error, "Input size mismatch: got %zu, expected %zu",
			       ai_input_msg.size, g_input_num_elements);
			ai_frame_gate_give();
			continue;
		}

		int8_t *input = static_cast<int8_t *>(g_input_data_ptr);
		uint32_t quant_start = k_cycle_get_32();

		for (size_t j = 0; j < ai_input_msg.size; j++) {
			input[j] = g_input_lut[ai_input_msg.data[j]];
		}
		ai_input_msg.timing.quant_us = k_cyc_to_us_floor32(k_cycle_get_32() - quant_start);

		/* ai_input_msg.data's bytes are fully copied out now, so camera.c's
		 * single-slot model_buffer_rgb is safe for camera_task to reuse. */
		k_sem_give(&ai_buffer_free_sem);

		ai_input_msg.timing.exec_start = k_cycle_get_32();
		Error status = (*g_method)->execute();
		ai_input_msg.timing.exec_end = k_cycle_get_32();
		uint32_t inference_us = k_cyc_to_us_floor32(ai_input_msg.timing.exec_end -
							    ai_input_msg.timing.exec_start);
		if (status != Error::Ok) {
			ET_LOG(Error, "Execution failed: 0x%" PRIx32,
			       static_cast<uint32_t>(status));
			ai_frame_gate_give();
			continue;
		}

		status = (*g_method)->get_outputs(g_outputs.data(), g_outputs.size());
		if (status != Error::Ok) {
			ET_LOG(Error, "get_outputs failed: 0x%" PRIx32,
			       static_cast<uint32_t>(status));
			ai_frame_gate_give();
			continue;
		}

		if (IS_ENABLED(CONFIG_APP_RUNTIME_LOG)) {
			ET_LOG(Info, "\n--- Loop inference ---");
		}
		get_top_k(g_outputs);
		ai_input_msg.timing.post_done = k_cycle_get_32();

		if (IS_ENABLED(CONFIG_APP_RUNTIME_LOG)) {
			ET_LOG(Info, "Inference time: %u us (%u ms)", inference_us,
			       inference_us / 1000);
		}

		ai_result_msg_t ai_result;
		ai_result.results = g_top_k_results;
		ai_result.inference_time_ms = inference_us / 1000;
		ai_result.result_count = AI_TOP_K;
		ai_result.timing = ai_input_msg.timing;
		if (k_msgq_put(ai_result_msgq, &ai_result, K_NO_WAIT) != 0) {
			ai_frame_gate_give();
		}
	}
}
```

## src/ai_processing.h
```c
/*
 * Copyright (c) 2026 Renesas Electronics Corporation
 *
 * SPDX-License-Identifier: Apache-2.0
 */
#ifndef _AI_PROCESSING_H_
#define _AI_PROCESSING_H_

#ifdef __cplusplus
extern "C" {
#endif

/* Loads the ExecuTorch program/method once. Must be called before ai_task. */
int ai_init(void);

void ai_task(void *arg1, void *arg2, void *arg3);

#ifdef __cplusplus
}
#endif

#endif
```

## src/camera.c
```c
/*
 * Copyright (c) 2026 Renesas Electronics Corporation
 *
 * SPDX-License-Identifier: Apache-2.0
 */

#include <zephyr/logging/log.h>
#include <zephyr/drivers/video.h>
#include <zephyr/drivers/video-controls.h>

#include "camera.h"
#include "common_util.h"

LOG_MODULE_REGISTER(camera, CONFIG_LOG_DEFAULT_LEVEL);

static uint8_t model_buffer_rgb[CONFIG_AI_INPUT_WIDTH * CONFIG_AI_INPUT_HEIGHT * 3] __aligned(4);
K_SEM_DEFINE(ai_buffer_free_sem, 1, 1);
#ifdef CONFIG_APP_SERIALIZE_FRAMES
K_SEM_DEFINE(ai_frame_gate_sem, 1, 1);
#endif
const struct device *video_dev;
static struct video_buffer *buffers[CONFIG_VIDEO_BUFFER_POOL_NUM_MAX];
static enum video_buf_type type = VIDEO_BUF_TYPE_OUTPUT;

static void set_control(const struct device *dev, uint32_t id, int32_t value)
{
	struct video_control ctrl = {
		.id = id,
		.val = value,
	};
	int ret = video_set_ctrl(dev, &ctrl);

	LOG_INF("Set CID=0x%x val=%d ret=%d", id, value, ret);
}

int camera_init(void)
{
	struct video_format fmt;
	struct video_caps caps;
	size_t bsize;
	int ret;

	video_dev = DEVICE_DT_GET(DT_CHOSEN(zephyr_camera));

	ret = device_is_ready(video_dev);
	if (ret < 0) {
		LOG_ERR("%s device is not ready", video_dev->name);
		return ret;
	}

	LOG_INF("- Device name: %s", video_dev->name);

	/* Get capabilities */
	caps.type = type;
	ret = video_get_caps(video_dev, &caps);
	if (ret < 0) {
		LOG_ERR("Unable to retrieve video capabilities");
		return ret;
	}

	/* Get default/native format */
	fmt.type = type;
	ret = video_get_format(video_dev, &fmt);
	if (ret < 0) {
		LOG_ERR("Unable to retrieve video format");
		return ret;
	}

	fmt.width = CONFIG_VIDEO_WIDTH;
	fmt.height = CONFIG_VIDEO_HEIGHT;
	fmt.pixelformat = VIDEO_PIX_FMT_YUYV;
	ret = video_set_format(video_dev, &fmt);
	if (ret < 0) {
		LOG_ERR("Unable to set up video format %d", ret);
		return ret;
	}

	set_control(video_dev, VIDEO_CID_HFLIP, 1);

	/* Size to allocate for each buffer */
	bsize = fmt.pitch * fmt.height;

	/* Alloc video buffers and enqueue for capture */
	for (int i = 0; i < ARRAY_SIZE(buffers); i++) {
		buffers[i] = video_buffer_aligned_alloc(bsize, CONFIG_VIDEO_BUFFER_POOL_ALIGN,
							K_NO_WAIT);
		if (buffers[i] == NULL) {
			LOG_ERR("Unable to alloc video buffer");
			return -1;
		}
		buffers[i]->type = type;
		video_enqueue(video_dev, buffers[i]);
	}

	/* Start video capture */
	ret = video_stream_start(video_dev, type);
	if (ret < 0) {
		LOG_ERR("Unable to start capture (interface)");
		return ret;
	}

	LOG_INF("- Camera initialized and capture started");
	return 0;
}

int image_rgb565_to_planar_rgb888(const void *p_input_image_buff, void *p_output_image_buff,
				  uint16_t in_width, uint16_t in_height, uint16_t out_width,
				  uint16_t out_height)
{
	if ((p_input_image_buff == NULL) || (p_output_image_buff == NULL)) {
		return -EINVAL;
	}

	if (in_width < in_height) {
		return -EINVAL;
	}

	register uint16_t *p_input = (uint16_t *)p_input_image_buff;
	const uint32_t plane_size = (uint32_t)out_width * out_height;
	uint8_t *p_plane_r = (uint8_t *)p_output_image_buff;
	uint8_t *p_plane_g = p_plane_r + plane_size;
	uint8_t *p_plane_b = p_plane_g + plane_size;

	uint32_t crop_offset = (in_width - in_height) / 2;

	for (uint32_t y = 0; y < out_height; y++) {
		uint32_t y_offset = in_width * ((in_height * y) / out_height);
		uint16_t *p_input_base = p_input + crop_offset + y_offset;
		uint32_t row = y * out_width;

		for (uint32_t x = 0; x < out_width; x++) {
			uint16_t input = *(p_input_base + ((in_height * x) / out_width));

			uint8_t r = (input >> 11) & 0x1F;
			uint8_t g = (input >> 5) & 0x3F;
			uint8_t b = input & 0x1F;

			p_plane_r[row + x] = (r * 255) / 31;
			p_plane_g[row + x] = (g * 255) / 63;
			p_plane_b[row + x] = (b * 255) / 31;
		}
	}

	return 0;
}

void camera_task(void *arg1, void *arg2, void *arg3)
{
	ARG_UNUSED(arg3);

	struct video_buffer *vbuf = &(struct video_buffer){};
	int err;
	struct k_msgq *display_frame_msgq = (struct k_msgq *)arg1;
	struct k_msgq *ai_raw_frame_msgq = (struct k_msgq *)arg2;
	camera_frame_msg_t camera_frame_msg;

	vbuf->type = type;

	while (1) {
		err = video_dequeue(video_dev, &vbuf, K_FOREVER);
		if (err) {
			LOG_ERR("Unable to dequeue video buf");
			continue;
		}

		camera_frame_msg.capture = k_cycle_get_32();
		camera_frame_msg.vbuf = vbuf;
		camera_frame_msg.video_dev = (struct device *)video_dev;

		if (k_msgq_num_free_get(ai_raw_frame_msgq) > 0 && ai_frame_gate_take()) {
			err = k_msgq_put(ai_raw_frame_msgq, &camera_frame_msg, K_NO_WAIT);
			if (err) {
				LOG_ERR("Failed to put frame into AI raw frame queue");
				ai_frame_gate_give();
			}
		}

		err = k_msgq_put(display_frame_msgq, &camera_frame_msg, K_NO_WAIT);
		if (err) {
			video_enqueue(video_dev, vbuf);
		}
	}
}

void camera_ai_preprocess_task(void *arg1, void *arg2, void *arg3)
{
	ARG_UNUSED(arg3);

	struct k_msgq *ai_raw_frame_msgq = (struct k_msgq *)arg1;
	struct k_msgq *ai_input_msgq = (struct k_msgq *)arg2;
	camera_frame_msg_t camera_frame_msg;
	ai_input_msg_t ai_input_msg;
	int err;

	while (1) {
		if (k_msgq_get(ai_raw_frame_msgq, &camera_frame_msg, K_FOREVER) != 0) {
			continue;
		}

		if (k_sem_take(&ai_buffer_free_sem, K_NO_WAIT) != 0) {
			ai_frame_gate_give();
			continue;
		}

		uint32_t convert_start = k_cycle_get_32();

		image_rgb565_to_planar_rgb888(
			&camera_frame_msg.vbuf->buffer[0], &model_buffer_rgb[0], CONFIG_VIDEO_WIDTH,
			CONFIG_VIDEO_HEIGHT, CONFIG_AI_INPUT_WIDTH, CONFIG_AI_INPUT_HEIGHT);
		ai_input_msg.timing.capture = camera_frame_msg.capture;
		ai_input_msg.timing.convert_us =
			k_cyc_to_us_floor32(k_cycle_get_32() - convert_start);
		ai_input_msg.size = sizeof(model_buffer_rgb);
		ai_input_msg.data = &model_buffer_rgb[0];

		err = k_msgq_put(ai_input_msgq, &ai_input_msg, K_NO_WAIT);
		if (err) {
			LOG_ERR("Failed to put frame into AI input queue");
			ai_frame_gate_give();
		}
	}
}
```

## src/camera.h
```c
/*
 * Copyright (c) 2026 Renesas Electronics Corporation
 *
 * SPDX-License-Identifier: Apache-2.0
 */
#ifndef _CAMERA_HANDLE_H_
#define _CAMERA_HANDLE_H_

int camera_init(void);

void camera_task(void *arg1, void *arg2, void *arg3);

void camera_ai_preprocess_task(void *arg1, void *arg2, void *arg3);

#endif
```

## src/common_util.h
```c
/*
 * Copyright (c) 2026 Renesas Electronics Corporation
 *
 * SPDX-License-Identifier: Apache-2.0
 */

#ifndef COMMON_UTIL_H__
#define COMMON_UTIL_H__

#include <stddef.h>
#include <stdint.h>
#include <zephyr/kernel.h>
#include <zephyr/drivers/video.h>

#define DISPLAY_QUEUE_DEPTH   CONFIG_VIDEO_BUFFER_POOL_NUM_MAX

extern struct k_sem ai_buffer_free_sem;
#define AI_RAW_FRAME_QUEUE_DEPTH 1
#define AI_INPUT_QUEUE_DEPTH  1
#define AI_RESULT_QUEUE_DEPTH 1

#define CAMERA_THREAD_PRIORITY       -4
#define AI_PREPROCESS_THREAD_PRIORITY -3
#define DISPLAY_THREAD_PRIORITY      -2
#define AI_THREAD_PRIORITY           -1

/* Timestamps (k_cycle_get_32) and durations collected as one frame moves
 * through the pipeline; only consumed when CONFIG_APP_PROFILING is set.
 */
typedef struct {
	uint32_t capture;    /* camera_task dequeued the frame from VIN */
	uint32_t convert_us; /* RGB565 -> planar RGB888 crop/resize */
	uint32_t quant_us;   /* uint8 -> model input LUT */
	uint32_t exec_start; /* just before Method::execute() */
	uint32_t exec_end;   /* Method::execute() returned */
	uint32_t post_done;  /* get_outputs() + get_top_k() finished */
} frame_timing_t;

#ifdef CONFIG_APP_SERIALIZE_FRAMES
/* One AI frame in flight: taken when camera_task hands a frame to the AI
 * pipeline, given when its result has been flushed (or the frame is dropped).
 */
extern struct k_sem ai_frame_gate_sem;

static inline bool ai_frame_gate_take(void)
{
	return k_sem_take(&ai_frame_gate_sem, K_NO_WAIT) == 0;
}

static inline void ai_frame_gate_give(void)
{
	k_sem_give(&ai_frame_gate_sem);
}
#else
static inline bool ai_frame_gate_take(void)
{
	return true;
}

static inline void ai_frame_gate_give(void)
{
}
#endif

typedef struct {
	size_t size;
	uint8_t *data;
	frame_timing_t timing;
} ai_input_msg_t;

typedef struct {
	uint32_t label_idx;
	const char *label;
	float probability;
} st_ai_classification_point_t;

typedef struct {
	st_ai_classification_point_t *results;
	uint32_t inference_time_ms;
	uint8_t result_count;
	frame_timing_t timing;
} ai_result_msg_t;

typedef struct {
	struct video_buffer *vbuf;
	struct device *video_dev;
	uint32_t capture; /* k_cycle_get_32() when camera_task dequeued it */
} camera_frame_msg_t;

#endif /* COMMON_UTIL_H__ */
```

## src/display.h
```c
/*
 * Copyright (c) 2026 Renesas Electronics Corporation
 *
 * SPDX-License-Identifier: Apache-2.0
 */

#ifndef _DISPLAY_HANDLE_H_
#define _DISPLAY_HANDLE_H_

#ifdef __cplusplus
extern "C" {
#endif

int display_init(void);

void display_task(void *arg1, void *arg2, void *arg3);

#ifdef __cplusplus
}
#endif

#endif
```
